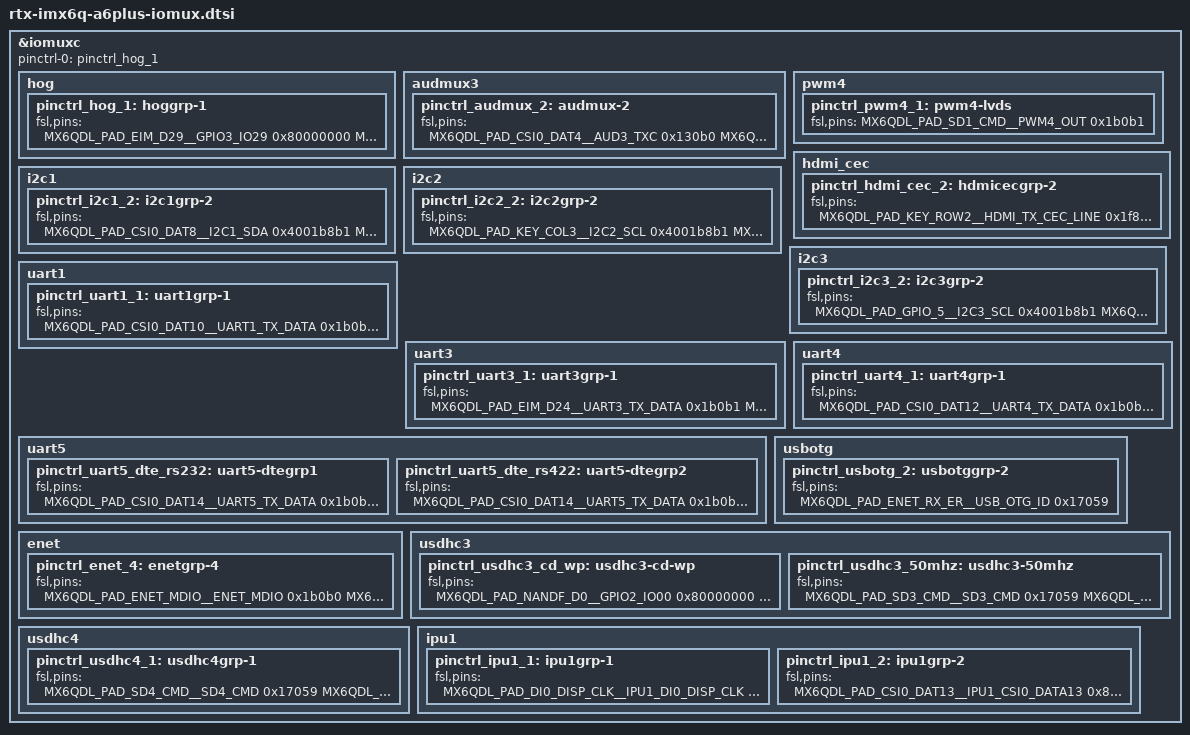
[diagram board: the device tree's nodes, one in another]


&iomuxc {
	pinctrl-names = "default";
	pinctrl-0 = <&pinctrl_hog_1>;

	hog {
		pinctrl_hog_1: hoggrp-1 {
			fsl,pins = <
				/* KEY BTN */
				MX6QDL_PAD_EIM_D29__GPIO3_IO29 				0x80000000	/* PWR_BTN_SNS */

				MX6QDL_PAD_EIM_D22__GPIO3_IO22				0x000b0		/* USB_OTG_PWR_EN */
				MX6QDL_PAD_EIM_D21__USB_OTG_OC				0x1b0b0		/* USB_OTG_OC */

				MX6QDL_PAD_ENET_TXD1__GPIO1_IO29			0x000b0		/* USB_H1_PWR_EN */
				MX6QDL_PAD_EIM_D30__USB_H1_OC				0x1b0b0		/* USB_H1_OC */
				MX6QDL_PAD_GPIO_17__GPIO7_IO12				0x80000000	/* USB_HUB_RESET_B */
				MX6QDL_PAD_NANDF_CS2__GPIO6_IO15			0x80000000	/* USB_PWR1 */
				MX6QDL_PAD_NANDF_CS3__GPIO6_IO16			0x80000000	/* USB_PWR2 */
				MX6QDL_PAD_NANDF_D4__GPIO2_IO04				0x80000000	/* USB_PWR3 */
				MX6QDL_PAD_NANDF_D5__GPIO2_IO05				0x80000000	/* USB_PWR4 */

				MX6QDL_PAD_GPIO_1__WDOG2_B				0x80000000	/* WDOG_B to reset pmic */

				/* LVDS */
				MX6QDL_PAD_SD1_DAT1__GPIO1_IO17				0x80000000	/* LVDS_BLEN */
				MX6QDL_PAD_GPIO_2__GPIO1_IO02				0x80000000	/*LCD_BKLT_EN*/
				MX6QDL_PAD_GPIO_9__GPIO1_IO09				0x80000000	/*ADJ_PNL*/
				MX6QDL_PAD_NANDF_D3__GPIO2_IO03				0x80000000	/* LCD_12V_EN */
				MX6QDL_PAD_GPIO_7__GPIO1_IO07				0x80000000	/* LCD_12_24V_EN */


				/* GPIO */
				MX6QDL_PAD_GPIO_19__GPIO4_IO05				0x80000000	/*DVI_I2C_ENB*/
				MX6QDL_PAD_GPIO_4__GPIO1_IO04				0x80000000	/*VDAC_STBY_B_GPIO3_8*/
				MX6QDL_PAD_ENET_TX_EN__GPIO1_IO28			0x80000000	/* GPIO 1 (28) */
				MX6QDL_PAD_ENET_RXD0__GPIO1_IO27			0x80000000	/* GPIO 2 (27) */
				MX6QDL_PAD_ENET_TXD0__GPIO1_IO30			0x80000000	/* GPIO 3 (30) */
				MX6QDL_PAD_KEY_COL1__GPIO4_IO08				0x80000000	/* GPIO 4 (104) */
				MX6QDL_PAD_KEY_ROW1__GPIO4_IO09				0x80000000	/* GPIO 5 (105) */
				MX6QDL_PAD_EIM_D26__GPIO3_IO26				0x80000000	/* GPIO 6 (90) */
				MX6QDL_PAD_EIM_D27__GPIO3_IO27				0x80000000	/* GPIO 7 (91) */


				/* Audio Codec */
				MX6QDL_PAD_GPIO_0__CCM_CLKO1				0x130b0		/* SGTL5000 sys_mclk */
				MX6QDL_PAD_EIM_D28__GPIO3_IO28				0x80000000	/* MICROPHONE_DET */
				MX6QDL_PAD_SD3_RST__GPIO7_IO08				0x80000000	/* HEADPHONE_DET */
				MX6QDL_PAD_CSI0_DAT18__GPIO6_IO04			0x80000000	/* HEADPHONE POP enable */
				MX6QDL_PAD_NANDF_D6__GPIO2_IO06				0x80000000	/* AMP STBY_B */
				MX6QDL_PAD_NANDF_D7__GPIO2_IO07				0x80000000	/* AMP MUTE_B */

				MX6QDL_PAD_SD3_DAT5__GPIO7_IO00				0x80000000	/* IR_C */
				MX6QDL_PAD_SD3_DAT6__GPIO6_IO18				0x80000000	/* LED_R_C */
				MX6QDL_PAD_SD3_DAT7__GPIO6_IO17				0x80000000	/* LED_G_C */
				MX6QDL_PAD_KEY_COL0__GPIO4_IO06				0x80000000	/* MCU_RESETn */
				MX6QDL_PAD_KEY_ROW0__GPIO4_IO07				0x80000000	/* MCU_UPDATE_PWR_ON */
				MX6QDL_PAD_KEY_COL2__GPIO4_IO10				0x80000000	/* MCU_BOOT_EN */

				MX6QDL_PAD_EIM_D18__GPIO3_IO18				0x80000000	/* PCIE_PWR_EN */
				MX6QDL_PAD_GPIO_16__GPIO7_IO11				0x80000000	/* PCIE_RST */
				MX6QDL_PAD_GPIO_8__GPIO1_IO08				0x80000000	/* PCIE_WAKE_B */
				MX6QDL_PAD_SD3_DAT4__GPIO7_IO01				0x80000000	/* PCIE_DIS_B */

				MX6QDL_PAD_EIM_D23__GPIO3_IO23				0x80000000	/* UART3_CTS */
				MX6QDL_PAD_EIM_D31__GPIO3_IO31				0x80000000	/* UART3_RTS */

				MX6QDL_PAD_EIM_CS1__GPIO2_IO24				0x80000000	/* UART5_M1 */
				MX6QDL_PAD_EIM_CS0__GPIO2_IO23				0x80000000	/* UART5_M0 */
				MX6QDL_PAD_EIM_D16__GPIO3_IO16				0x80000000	/* UART5 enable */
				MX6QDL_PAD_EIM_D17__GPIO3_IO17				0x80000000	/* UART5 slew */
				MX6QDL_PAD_EIM_BCLK__GPIO6_IO31				0x80000000	/* UART5 TERM */
			>;
		};
	};

	audmux3 {
		pinctrl_audmux_2: audmux-2 {
			fsl,pins = <
				MX6QDL_PAD_CSI0_DAT4__AUD3_TXC  			0x130b0
				MX6QDL_PAD_CSI0_DAT5__AUD3_TXD  			0x110b0
				MX6QDL_PAD_CSI0_DAT6__AUD3_TXFS 			0x130b0
				MX6QDL_PAD_CSI0_DAT7__AUD3_RXD  			0x130b0
			>;
		};
	};

	pwm4 {
		pinctrl_pwm4_1: pwm4-lvds {
			fsl,pins = <
				MX6QDL_PAD_SD1_CMD__PWM4_OUT				0x1b0b1		/* LVDS_BLT_CTRL PWM */
			>;
		};
	};

	hdmi_cec {
		pinctrl_hdmi_cec_2: hdmicecgrp-2 {
			fsl,pins = <
				MX6QDL_PAD_KEY_ROW2__HDMI_TX_CEC_LINE 			0x1f8b0
			>;
		};
	};

	i2c1 {
		pinctrl_i2c1_2: i2c1grp-2 {
			fsl,pins = <
				MX6QDL_PAD_CSI0_DAT8__I2C1_SDA 				0x4001b8b1
				MX6QDL_PAD_CSI0_DAT9__I2C1_SCL 				0x4001b8b1
			>;
		};
	};

	i2c2 {
		pinctrl_i2c2_2: i2c2grp-2 {
			fsl,pins = <
				MX6QDL_PAD_KEY_COL3__I2C2_SCL 				0x4001b8b1
				MX6QDL_PAD_KEY_ROW3__I2C2_SDA 				0x4001b8b1
			>;
		};
	};

	i2c3 {
		pinctrl_i2c3_2: i2c3grp-2 {
			fsl,pins = <
				MX6QDL_PAD_GPIO_5__I2C3_SCL 				0x4001b8b1
				MX6QDL_PAD_GPIO_6__I2C3_SDA 				0x4001b8b1
			>;
		};
	};

	uart1 {
		pinctrl_uart1_1: uart1grp-1 {
			fsl,pins = <
				MX6QDL_PAD_CSI0_DAT10__UART1_TX_DATA 			0x1b0b1
				MX6QDL_PAD_CSI0_DAT11__UART1_RX_DATA 			0x1b0b1
				MX6QDL_PAD_EIM_D19__UART1_CTS_B				0x1b0b1
				MX6QDL_PAD_EIM_D20__UART1_RTS_B				0x1b0b1
			>;
		};
	};

	uart3 {
		pinctrl_uart3_1: uart3grp-1 {
			fsl,pins = <
				MX6QDL_PAD_EIM_D24__UART3_TX_DATA 			0x1b0b1
				MX6QDL_PAD_EIM_D25__UART3_RX_DATA 			0x1b0b1
			>;
		};
	};

	uart4 {
		pinctrl_uart4_1: uart4grp-1 {
			fsl,pins = <
				MX6QDL_PAD_CSI0_DAT12__UART4_TX_DATA 			0x1b0b1
				MX6QDL_PAD_CSI0_DAT13__UART4_RX_DATA 			0x1b0b1
				MX6QDL_PAD_CSI0_DAT17__UART4_CTS_B 			0x1b0b1
				MX6QDL_PAD_CSI0_DAT16__UART4_RTS_B 			0x1b0b1
			>;
		};
	};

	uart5 {
		/* DTE mode */
		pinctrl_uart5_dte_rs232: uart5-dtegrp1 {
			fsl,pins = <
				MX6QDL_PAD_CSI0_DAT14__UART5_TX_DATA			0x1b0b1
				MX6QDL_PAD_CSI0_DAT15__UART5_RX_DATA			0x1b0b1
				MX6QDL_PAD_KEY_ROW4__UART5_CTS_B			0x1b0b1
				MX6QDL_PAD_KEY_COL4__UART5_RTS_B			0x1b0b1
			>;
		};
		pinctrl_uart5_dte_rs422: uart5-dtegrp2 {
			fsl,pins = <
				MX6QDL_PAD_CSI0_DAT14__UART5_TX_DATA			0x1b0b1
				MX6QDL_PAD_CSI0_DAT15__UART5_RX_DATA			0x1b0b1
				MX6QDL_PAD_KEY_ROW4__GPIO4_IO15				0x80000000
				MX6QDL_PAD_KEY_COL4__UART5_RTS_B			0x1b0b1
			>;
		};
	};

	usbotg {
		pinctrl_usbotg_2: usbotggrp-2 {
			fsl,pins = <
				MX6QDL_PAD_ENET_RX_ER__USB_OTG_ID 			0x17059
			>;
		};
	};

	enet {
		pinctrl_enet_4: enetgrp-4 {
			fsl,pins = <
				MX6QDL_PAD_ENET_MDIO__ENET_MDIO				0x1b0b0		/* RGMII_MDIO */
				MX6QDL_PAD_ENET_MDC__ENET_MDC				0x1b0b0		/* RGMII_MDC */
				MX6QDL_PAD_RGMII_TXC__RGMII_TXC				0x1b0b0
				MX6QDL_PAD_RGMII_TD0__RGMII_TD0				0x1b0b0
				MX6QDL_PAD_RGMII_TD1__RGMII_TD1				0x1b0b0
				MX6QDL_PAD_RGMII_TD2__RGMII_TD2				0x1b0b0
				MX6QDL_PAD_RGMII_TD3__RGMII_TD3				0x1b0b0
				MX6QDL_PAD_RGMII_TX_CTL__RGMII_TX_CTL			0x1b0b0
				MX6QDL_PAD_ENET_REF_CLK__ENET_TX_CLK			0x4001b0a8	/* ENET_REFCLK */
				MX6QDL_PAD_RGMII_RXC__RGMII_RXC				0x1b0b0
				MX6QDL_PAD_RGMII_RD0__RGMII_RD0				0x1b0b0
				MX6QDL_PAD_RGMII_RD1__RGMII_RD1				0x1b0b0
				MX6QDL_PAD_RGMII_RD2__RGMII_RD2				0x1b0b0
				MX6QDL_PAD_RGMII_RD3__RGMII_RD3				0x1b0b0
				MX6QDL_PAD_RGMII_RX_CTL__RGMII_RX_CTL			0x1b0b0
				MX6QDL_PAD_ENET_RXD1__GPIO1_IO26			0x000b1		/* RGMII_INT */
				MX6QDL_PAD_ENET_CRS_DV__GPIO1_IO25			0x1b0b0		/* RGMII_nRST */
			>;
		};
	};

	usdhc3 {
		pinctrl_usdhc3_cd_wp: usdhc3-cd-wp {
			fsl,pins = <
				MX6QDL_PAD_NANDF_D0__GPIO2_IO00				0x80000000	/* SD3_CD */
				MX6QDL_PAD_NANDF_D1__GPIO2_IO01				0x80000000	/* SD3_WP */
			>;
		};

		pinctrl_usdhc3_50mhz: usdhc3-50mhz {							/* 50Mhz */
			fsl,pins = <
				MX6QDL_PAD_SD3_CMD__SD3_CMD				0x17059
				MX6QDL_PAD_SD3_CLK__SD3_CLK				0x10059
				MX6QDL_PAD_SD3_DAT0__SD3_DATA0				0x17059
				MX6QDL_PAD_SD3_DAT1__SD3_DATA1				0x17059
				MX6QDL_PAD_SD3_DAT2__SD3_DATA2				0x17059
				MX6QDL_PAD_SD3_DAT3__SD3_DATA3				0x17059
			>;
		};
	};

	usdhc4 {
		pinctrl_usdhc4_1: usdhc4grp-1 {
			fsl,pins = <
				MX6QDL_PAD_SD4_CMD__SD4_CMD    				0x17059
				MX6QDL_PAD_SD4_CLK__SD4_CLK    				0x10059
				MX6QDL_PAD_SD4_DAT0__SD4_DATA0 				0x17059
				MX6QDL_PAD_SD4_DAT1__SD4_DATA1 				0x17059
				MX6QDL_PAD_SD4_DAT2__SD4_DATA2 				0x17059
				MX6QDL_PAD_SD4_DAT3__SD4_DATA3 				0x17059
				MX6QDL_PAD_SD4_DAT4__SD4_DATA4 				0x17059
				MX6QDL_PAD_SD4_DAT5__SD4_DATA5 				0x17059
				MX6QDL_PAD_SD4_DAT6__SD4_DATA6 				0x17059
				MX6QDL_PAD_SD4_DAT7__SD4_DATA7 				0x17059
			>;
		};
	};

	ipu1 {
		pinctrl_ipu1_1: ipu1grp-1 {
			fsl,pins = <
				MX6QDL_PAD_DI0_DISP_CLK__IPU1_DI0_DISP_CLK 	0x10
				MX6QDL_PAD_DI0_PIN15__IPU1_DI0_PIN15       	0x10
				MX6QDL_PAD_DI0_PIN2__IPU1_DI0_PIN02        	0x10
				MX6QDL_PAD_DI0_PIN3__IPU1_DI0_PIN03        	0x10
				MX6QDL_PAD_DI0_PIN4__IPU1_DI0_PIN04        	0x10
				MX6QDL_PAD_DISP0_DAT0__IPU1_DISP0_DATA00   	0x10
				MX6QDL_PAD_DISP0_DAT1__IPU1_DISP0_DATA01   	0x10
				MX6QDL_PAD_DISP0_DAT2__IPU1_DISP0_DATA02   	0x10
				MX6QDL_PAD_DISP0_DAT3__IPU1_DISP0_DATA03   	0x10
				MX6QDL_PAD_DISP0_DAT4__IPU1_DISP0_DATA04   	0x10
				MX6QDL_PAD_DISP0_DAT5__IPU1_DISP0_DATA05   	0x10
				MX6QDL_PAD_DISP0_DAT6__IPU1_DISP0_DATA06   	0x10
				MX6QDL_PAD_DISP0_DAT7__IPU1_DISP0_DATA07   	0x10
				MX6QDL_PAD_DISP0_DAT8__IPU1_DISP0_DATA08   	0x10
				MX6QDL_PAD_DISP0_DAT9__IPU1_DISP0_DATA09   	0x10
				MX6QDL_PAD_DISP0_DAT10__IPU1_DISP0_DATA10  	0x10
				MX6QDL_PAD_DISP0_DAT11__IPU1_DISP0_DATA11  	0x10
				MX6QDL_PAD_DISP0_DAT12__IPU1_DISP0_DATA12  	0x10
				MX6QDL_PAD_DISP0_DAT13__IPU1_DISP0_DATA13  	0x10
				MX6QDL_PAD_DISP0_DAT14__IPU1_DISP0_DATA14  	0x10
				MX6QDL_PAD_DISP0_DAT15__IPU1_DISP0_DATA15  	0x10
				MX6QDL_PAD_DISP0_DAT16__IPU1_DISP0_DATA16  	0x10
				MX6QDL_PAD_DISP0_DAT17__IPU1_DISP0_DATA17  	0x10
				MX6QDL_PAD_DISP0_DAT18__IPU1_DISP0_DATA18  	0x10
				MX6QDL_PAD_DISP0_DAT19__IPU1_DISP0_DATA19  	0x10
				MX6QDL_PAD_DISP0_DAT20__IPU1_DISP0_DATA20  	0x10
				MX6QDL_PAD_DISP0_DAT21__IPU1_DISP0_DATA21  	0x10
				MX6QDL_PAD_DISP0_DAT22__IPU1_DISP0_DATA22  	0x10
				MX6QDL_PAD_DISP0_DAT23__IPU1_DISP0_DATA23  	0x10
			>;
		};

		pinctrl_ipu1_2: ipu1grp-2 { 								/* parallel camera */
			fsl,pins = <
				MX6QDL_PAD_CSI0_DAT13__IPU1_CSI0_DATA13    	0x80000000
				MX6QDL_PAD_CSI0_DAT14__IPU1_CSI0_DATA14    	0x80000000
				MX6QDL_PAD_CSI0_DAT15__IPU1_CSI0_DATA15    	0x80000000
				MX6QDL_PAD_CSI0_DAT16__IPU1_CSI0_DATA16    	0x80000000
				MX6QDL_PAD_CSI0_DAT17__IPU1_CSI0_DATA17    	0x80000000
				MX6QDL_PAD_CSI0_DAT18__IPU1_CSI0_DATA18    	0x80000000
				MX6QDL_PAD_CSI0_DAT19__IPU1_CSI0_DATA19    	0x80000000
				MX6QDL_PAD_CSI0_DATA_EN__IPU1_CSI0_DATA_EN 	0x80000000
				MX6QDL_PAD_CSI0_PIXCLK__IPU1_CSI0_PIXCLK   	0x80000000
				MX6QDL_PAD_CSI0_MCLK__IPU1_CSI0_HSYNC      	0x80000000
				MX6QDL_PAD_CSI0_VSYNC__IPU1_CSI0_VSYNC     	0x80000000
			>;
		};
	};
};

